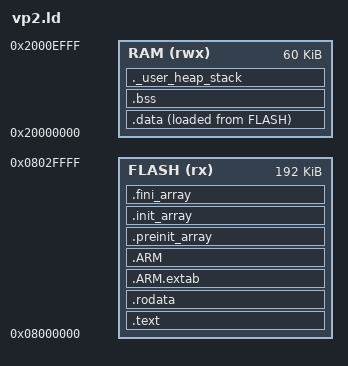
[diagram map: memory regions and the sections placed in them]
ENTRY(_start)

RAM_origin = 0x20000000;
RAM_length = 60K;
FLASH_origin = 0x08000000;
FLASH_length = 192K;
_estack = RAM_origin + RAM_length;

MEMORY {
	RAM(rwx)  : ORIGIN = RAM_origin, LENGTH = RAM_length
	FLASH(rx) : ORIGIN = FLASH_origin, LENGTH = FLASH_length
}

SECTIONS {
  .text : {
    . = ALIGN(4);
    *(.text.bootloader)
    *(.text)           /* .text sections (code) */
    *(.text*)          /* .text* sections (code) */
    *(.glue_7)         /* glue arm to thumb code */
    *(.glue_7t)        /* glue thumb to arm code */
    *(.eh_frame)
    KEEP (*(.init))
    KEEP (*(.fini))
    . = ALIGN(4);
    _etext = .;        /* define a global symbols at end of code */
  } > FLASH
  .rodata : {
    . = ALIGN(4);
    *(.rodata)         /* .rodata sections (constants, strings, etc.) */
    *(.rodata*)        /* .rodata* sections (constants, strings, etc.) */
    . = ALIGN(4);
  } > FLASH
  .ARM.extab : { *(.ARM.extab* .gnu.linkonce.armextab.*) } >FLASH
  .ARM : {
    __exidx_start = .;
    *(.ARM.exidx*)
    __exidx_end = .;
  } > FLASH
  .preinit_array : {
    PROVIDE_HIDDEN (__preinit_array_start = .);
    KEEP (*(.preinit_array*))
    PROVIDE_HIDDEN (__preinit_array_end = .);
  } > FLASH
  .init_array : {
    PROVIDE_HIDDEN (__init_array_start = .);
    KEEP (*(SORT(.init_array.*)))
    KEEP (*(.init_array*))
    PROVIDE_HIDDEN (__init_array_end = .);
  } > FLASH
  .fini_array : {
    PROVIDE_HIDDEN (__fini_array_start = .);
    KEEP (*(SORT(.fini_array.*)))
    KEEP (*(.fini_array*))
    PROVIDE_HIDDEN (__fini_array_end = .);
  } > FLASH
  _sidata = LOADADDR(.data);
  .data : {
    . = ALIGN(4);
    _sdata = .;        /* create a global symbol at data start */
    *(.data)           /* .data sections */
    *(.data*)          /* .data* sections */
    . = ALIGN(4);
    _edata = .;        /* define a global symbol at data end */
  } > RAM AT > FLASH
  . = ALIGN(4);
  .bss : {
    _sbss = .;         /* define a global symbol at bss start */
    __bss_start__ = _sbss;
    *(.bss)
    *(.bss*)
    *(COMMON)
    . = ALIGN(4);
    _ebss = .;         /* define a global symbol at bss end */
    __bss_end__ = _ebss;
  } > RAM
  ._user_heap_stack : {
    . = ALIGN(8);
    PROVIDE ( end = . );
    PROVIDE ( _end = . );
	__end__ = .;
  } >RAM
  /DISCARD/ : {
    libc.a ( * )
    libm.a ( * )
    libgcc.a ( * )
  }
  .ARM.attributes 0 : { *(.ARM.attributes) }
}
